# STM32L053 register map
File version: 1.0
CPU: CM0+ r0p0, little endian, MPU, no FPU, 4 interrupt priority bits
Registers are 32-bit, read-write, reset 0x0 unless marked. A register's access mark holds for its fields unless they carry their own. Offsets are from the block's base; [hi:lo] are bit positions.

## DBGMCU — Debug support
Base 0x40015800
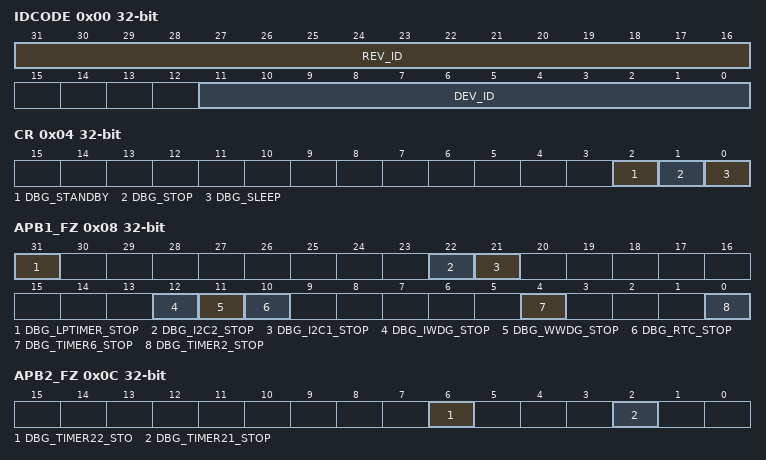
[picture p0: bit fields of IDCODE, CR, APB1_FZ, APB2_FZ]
0x00 IDCODE ro — MCU Device ID Code Register
  [31:16] REV_ID — Revision Identifier
  [11:0] DEV_ID — Device Identifier
0x04 CR — Debug MCU Configuration Register
  [2] DBG_STANDBY — Debug Standby Mode
  [1] DBG_STOP — Debug Stop Mode
  [0] DBG_SLEEP — Debug Sleep Mode
0x08 APB1_FZ — APB Low Freeze Register
  [31] DBG_LPTIMER_STOP — LPTIM1 counter stopped when core is halted
  [22] DBG_I2C2_STOP — I2C2 SMBUS timeout mode stopped when core is halted
  [21] DBG_I2C1_STOP — I2C1 SMBUS timeout mode stopped when core is halted
  [12] DBG_IWDG_STOP — Debug Independent Wachdog stopped when Core is halted
  [11] DBG_WWDG_STOP — Debug Window Wachdog stopped when Core is halted
  [10] DBG_RTC_STOP — Debug RTC stopped when Core is halted
  [4] DBG_TIMER6_STOP — Debug Timer 6 stopped when Core is halted
  [0] DBG_TIMER2_STOP — Debug Timer 2 stopped when Core is halted
0x0C APB2_FZ — APB High Freeze Register
  [6] DBG_TIMER22_STO — Debug Timer 22 stopped when Core is halted
  [2] DBG_TIMER21_STOP — Debug Timer 21 stopped when Core is halted

## TIM6 — Basic-timers
Base 0x40001000
Same registers: TIM7 0x40001400
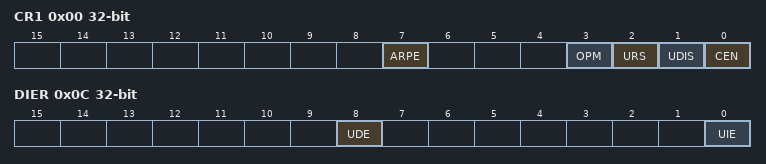
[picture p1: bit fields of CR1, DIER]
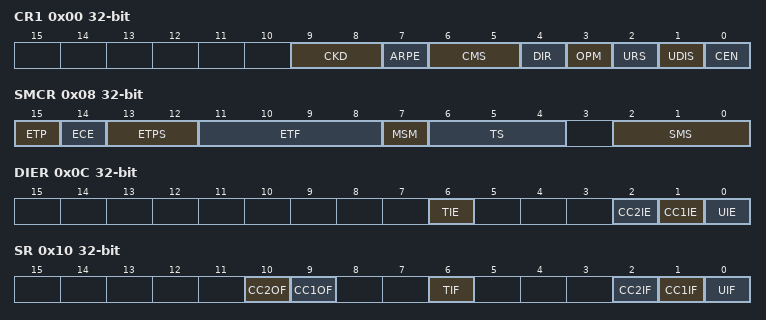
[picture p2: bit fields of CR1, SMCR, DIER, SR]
0x00 CR1 — control register 1
  [7] ARPE — Auto-reload preload enable
  [3] OPM — One-pulse mode
  [2] URS — Update request source
  [1] UDIS — Update disable
  [0] CEN — Counter enable
0x04 CR2 — control register 2
  [6:4] MMS — Master mode selection
0x0C DIER — DMA/Interrupt enable register
  [8] UDE — Update DMA request enable
  [0] UIE — Update interrupt enable
0x10 SR — status register
  [0] UIF — Update interrupt flag
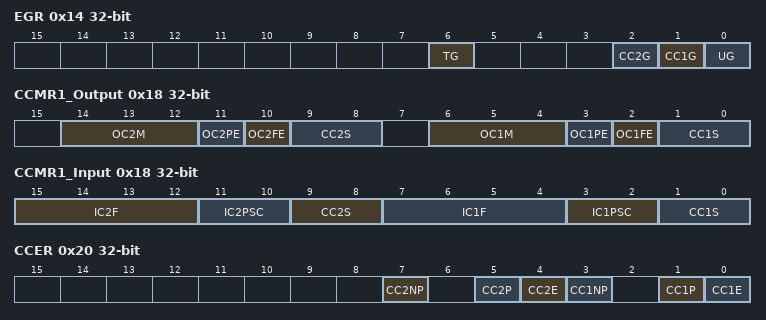
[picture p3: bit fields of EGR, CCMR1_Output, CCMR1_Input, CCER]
0x14 EGR wo — event generation register
  [0] UG — Update generation
0x24 CNT — counter
  [15:0] CNT — Low counter value
0x28 PSC — prescaler
  [15:0] PSC — Prescaler value
0x2C ARR — auto-reload register
  [15:0] ARR — Low Auto-reload value

## TIM21 — General-purpose-timers
Base 0x40010800
0x00 CR1 — control register 1
  [9:8] CKD — Clock division
  [7] ARPE — Auto-reload preload enable
  [6:5] CMS — Center-aligned mode selection
  [4] DIR — Direction
  [3] OPM — One-pulse mode
  [2] URS — Update request source
  [1] UDIS — Update disable
  [0] CEN — Counter enable
0x04 CR2 — control register 2
  [6:4] MMS — Master mode selection
0x08 SMCR — slave mode control register
  [15] ETP — External trigger polarity
  [14] ECE — External clock enable
  [13:12] ETPS — External trigger prescaler
  [11:8] ETF — External trigger filter
  [7] MSM — Master/Slave mode
  [6:4] TS — Trigger selection
  [2:0] SMS — Slave mode selection
0x0C DIER — DMA/Interrupt enable register
  [6] TIE — Trigger interrupt enable
  [2] CC2IE — Capture/Compare 2 interrupt enable
  [1] CC1IE — Capture/Compare 1 interrupt enable
  [0] UIE — Update interrupt enable
0x10 SR — status register
  [10] CC2OF — Capture/compare 2 overcapture flag
  [9] CC1OF — Capture/Compare 1 overcapture flag
  [6] TIF — Trigger interrupt flag
  [2] CC2IF — Capture/Compare 2 interrupt flag
  [1] CC1IF — Capture/compare 1 interrupt flag
  [0] UIF — Update interrupt flag
0x14 EGR wo — event generation register
  [6] TG — Trigger generation
  [2] CC2G — Capture/compare 2 generation
  [1] CC1G — Capture/compare 1 generation
  [0] UG — Update generation
0x18 CCMR1_Output — capture/compare mode register (output mode)
  [14:12] OC2M — Output Compare 2 mode
  [11] OC2PE — Output Compare 2 preload enable
  [10] OC2FE — Output Compare 2 fast enable
  [9:8] CC2S — Capture/Compare 2 selection
  [6:4] OC1M — Output Compare 1 mode
  [3] OC1PE — Output Compare 1 preload enable
  [2] OC1FE — Output Compare 1 fast enable
  [1:0] CC1S — Capture/Compare 1 selection
0x18 CCMR1_Input (alternate view of CCMR1_Output) — capture/compare mode register 1 (input mode)
  [15:12] IC2F — Input capture 2 filter
  [11:10] IC2PSC — Input capture 2 prescaler
  [9:8] CC2S — Capture/Compare 2 selection
  [7:4] IC1F — Input capture 1 filter
  [3:2] IC1PSC — Input capture 1 prescaler
  [1:0] CC1S — Capture/Compare 1 selection
0x20 CCER — capture/compare enable register
  [7] CC2NP — Capture/Compare 2 output Polarity
  [5] CC2P — Capture/Compare 2 output Polarity
  [4] CC2E — Capture/Compare 2 output enable
  [3] CC1NP — Capture/Compare 1 output Polarity
  [1] CC1P — Capture/Compare 1 output Polarity
  [0] CC1E — Capture/Compare 1 output enable
0x24 CNT — counter
  [15:0] CNT — counter value
0x28 PSC — prescaler
  [15:0] PSC — Prescaler value
0x2C ARR — auto-reload register
  [15:0] ARR — Auto-reload value
0x34 CCR1 — capture/compare register 1
  [15:0] CCR1 — Capture/Compare 1 value
0x38 CCR2 — capture/compare register 2
  [15:0] CCR2 — Capture/Compare 2 value
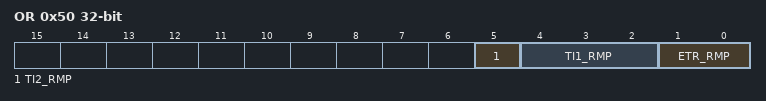
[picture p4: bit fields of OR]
0x50 OR — TIM21 option register
  [5] TI2_RMP — Timer21 TI2
  [4:2] TI1_RMP — Timer21 TI1
  [1:0] ETR_RMP — Timer21 ETR remap

## TIM22 — General-purpose-timers
Base 0x40011400
Registers as TIM21; these are added or differ:
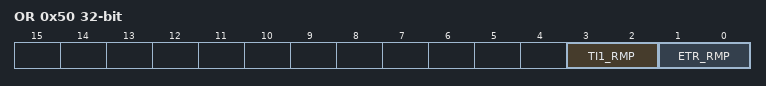
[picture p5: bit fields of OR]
0x50 OR — TIM22 option register
  [3:2] TI1_RMP — Timer22 TI1
  [1:0] ETR_RMP — Timer22 ETR remap
